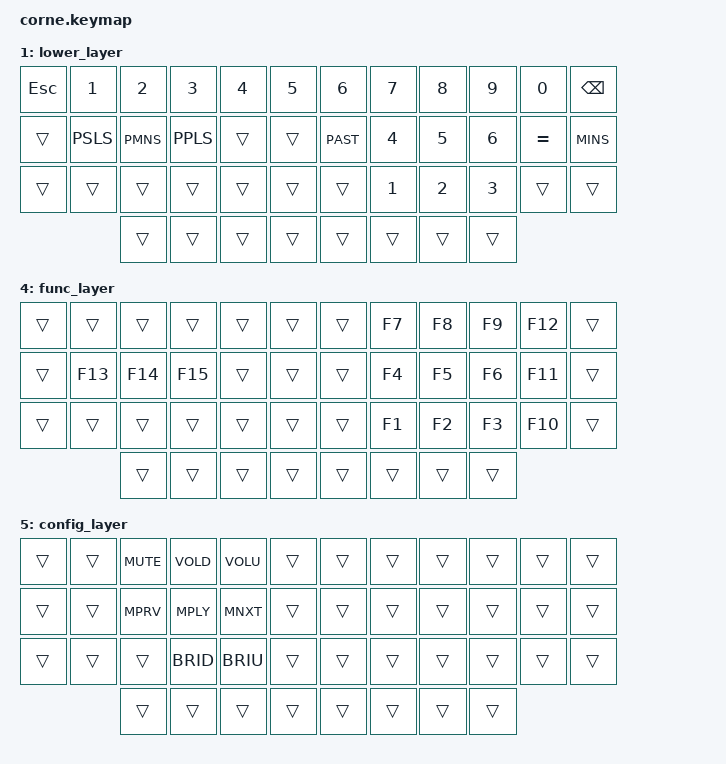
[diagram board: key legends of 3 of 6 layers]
/*
 * SPDX-License-Identifier: MIT
 */

#include <behaviors.dtsi>
#include <dt-bindings/zmk/keys.h>
#include <dt-bindings/zmk/bt.h>

/ {
    keymap {
        compatible = "zmk,keymap";

        // Default Layer
        default_layer {
            bindings = <
                &kp ESC    &kp Q      &kp W     &kp E     &kp R          &kp T       &kp Y     &kp U            &kp I     &kp O     &kp P      &kp BSPC
                &kp TAB    &kp A      &kp S     &kp D     &mo 1 &kp G     &kp H       &mo 5 &kp J &kp K         &kp L     &kp SEMI  &kp SQT
                &kp LSHFT  &kp Z      &kp X     &kp C     &mo 4 &kp V     &kp N       &kp M            &kp COMMA &kp DOT  &kp FSLH  &kp RSHFT
                                  &kp LALT   &kp LGUI  &mo 1 &kp BSPC    &mo 2 &kp SPC   &mo 3 &kp RCTL
            >;
        };

        // Lower Layer
        lower_layer {
            bindings = <
                &kp ESC    &kp N1     &kp N2    &kp N3    &kp N4         &kp N5      &kp N6    &kp N7           &kp N8    &kp N9    &kp N0     &kp BSPC
                &trans     &kp PSLS   &kp PMNS  &kp PPLS  &trans         &trans      &kp PAST  &kp N4           &kp N5    &kp N6    &kp EQL    &kp MINS
                &trans     &trans     &trans    &trans    &trans         &trans      &trans    &kp N1           &kp N2    &kp N3    &trans     &trans
                                  &trans      &trans     &trans          &trans      &trans    &trans           &trans    &trans
            >;
        };

        // Raise Layer
        raise_layer {
            bindings = <
                &kp TAB    &kp EXCL   &kp AT    &kp HASH  &kp DLLR       &kp PRCNT   &kp CARET &kp AMPS         &kp ASTRK &kp LPAR  &kp RPAR   &kp BSPC
                &kp LCTRL  &trans     &trans    &trans    &trans         &trans      &kp MINUS &kp EQUAL        &kp LBKT  &kp RBKT  &kp BSLH   &kp GRAVE
                &kp LSHFT  &trans     &trans    &trans    &trans         &trans      &kp UNDER &kp PLUS         &kp LBRC  &kp RBRC  &kp PIPE   &kp TILDE
                                  &kp LGUI   &trans     &kp SPACE       &kp RET     &trans    &kp RALT
            >;
        };

        // Nav Layer
        nav_layer {
            bindings = <
                &trans     &trans     &trans    &trans    &trans         &trans      &trans    &kp PG_UP        &kp UP    &kp RIGHT &trans     &trans
                &trans     &trans     &trans    &trans    &trans         &trans      &trans    &kp LEFT         &kp DOWN  &kp RIGHT &trans     &trans
                &trans     &trans     &trans    &trans    &trans         &trans      &trans    &kp PG_DN        &trans    &trans    &trans
                                  &trans      &trans     &trans          &trans      &trans    &trans           &trans    &trans
            >;
        };

        // Func Layer
        func_layer {
            bindings = <
                &trans     &trans     &trans    &trans    &trans         &trans      &trans    &kp F7           &kp F8    &kp F9    &kp F12    &trans
                &trans     &kp F13    &kp F14   &kp F15   &trans         &trans      &trans    &kp F4           &kp F5    &kp F6    &kp F11    &trans
                &trans     &trans     &trans    &trans    &trans         &trans      &trans    &kp F1           &kp F2    &kp F3    &kp F10    &trans
                                  &trans      &trans     &trans          &trans      &trans    &trans           &trans    &trans
            >;
        };

        // Config Layer
        config_layer {
            bindings = <
                &trans     &trans     &kp MUTE  &kp VOLD  &kp VOLU       &trans      &trans    &trans           &trans    &trans    &trans     &trans
                &trans     &trans     &kp MPRV  &kp MPLY  &kp MNXT       &trans      &trans    &trans           &trans    &trans    &trans     &trans
                &trans     &trans     &trans    &kp BRID  &kp BRIU       &trans      &trans    &trans           &trans    &trans    &trans     &trans
                                  &trans      &trans     &trans          &trans      &trans    &trans           &trans    &trans
            >;
        };

        // Combos
        combos {
            compatible = "zmk,combos";

            fbspc_del {
                timeout-ms = <50>;
                bindings = <&kp DEL>;
                key-positions = <10 11>; // Positions for KC_O and KC_BSPC
            };

            n9bspc_del {
                timeout-ms = <50>;
                bindings = <&kp DEL>;
                key-positions = <9 11>; // Positions for KC_9 and KC_BSPC
            };
        };
    };
};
